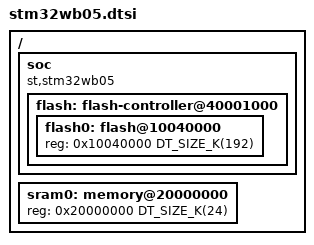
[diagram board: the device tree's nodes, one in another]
/*
 * Copyright (c) 2024 STMicroelectronics
 *
 * SPDX-License-Identifier: Apache-2.0
 */

#include <st/wb0/stm32wb05_09.dtsi>

/ {
	soc {
		compatible = "st,stm32wb05", "st,stm32wb0", "simple-bus";

		flash: flash-controller@40001000 {
			flash0: flash@10040000 {
				reg = <0x10040000 DT_SIZE_K(192)>;
			};
		};
	};

	sram0: memory@20000000 {
		reg = <0x20000000 DT_SIZE_K(24)>;
	};
};
